# AT91SAM9M10 register map
Vendor: Atmel; File version: 20130207
CPU: 
Registers are 32-bit, read-write, no defined reset value unless marked. A register's access mark holds for its fields unless they carry their own. Offsets are from the block's base; [hi:lo] are bit positions; {n}, {i} and the like mark numbered series.

## ISI — Image Sensor Interface
Base 0xFFFB4000
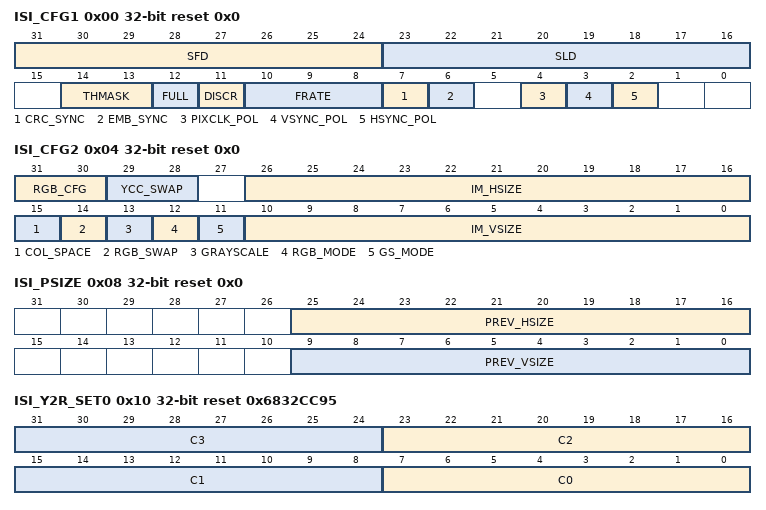
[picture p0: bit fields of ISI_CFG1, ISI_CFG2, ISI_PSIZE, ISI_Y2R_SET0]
0x00 ISI_CFG1 reset 0x0 — ISI Configuration 1 Register
  [31:24] SFD — Start of Frame Delay
  [23:16] SLD — Start of Line Delay
  [14:13] THMASK — Threshold Mask
  [12] FULL — Full Mode is Allowed
  [11] DISCR — Disable Codec Request
  [10:8] FRATE — Frame Rate [0..7]
  [7] CRC_SYNC — Embedded Synchronization Correction
  [6] EMB_SYNC — Embedded Synchronization
  [4] PIXCLK_POL — Pixel Clock Polarity
  [3] VSYNC_POL — Vertical Synchronization Polarity
  [2] HSYNC_POL — Horizontal Synchronization Polarity
0x04 ISI_CFG2 reset 0x0 — ISI Configuration 2 Register
  [31:30] RGB_CFG — Defines RGB Pattern when RGB_MODE is set to 1
  [29:28] YCC_SWAP — Defines the YCC Image Data
  [26:16] IM_HSIZE — Horizontal Size of the Image Sensor [0..2047]
  [15] COL_SPACE — Color Space for the Image Data
  [14] RGB_SWAP
  [13] GRAYSCALE
  [12] RGB_MODE — RGB Input Mode:
  [11] GS_MODE
  [10:0] IM_VSIZE — Vertical Size of the Image Sensor [0..2047]:
0x08 ISI_PSIZE reset 0x0 — ISI Preview Size Register
  [25:16] PREV_HSIZE — Horizontal Size for the Preview Path
  [9:0] PREV_VSIZE — Vertical Size for the Preview Path
0x0C ISI_PDECF reset 0x10 — ISI Preview Decimation Factor Register
  [7:0] DEC_FACTOR — Decimation Factor
0x10 ISI_Y2R_SET0 reset 0x6832CC95 — ISI CSC YCrCb To RGB Set 0 Register
  [8n+7:8n] C{n} (n=0..3) — Color Space Conversion Matrix Coefficient C{n}
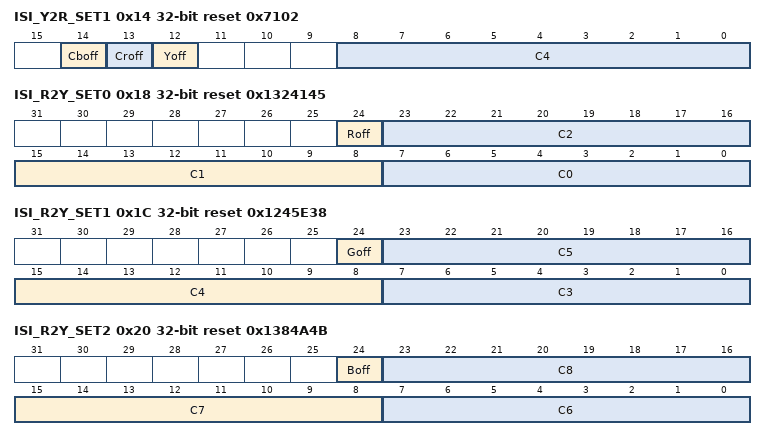
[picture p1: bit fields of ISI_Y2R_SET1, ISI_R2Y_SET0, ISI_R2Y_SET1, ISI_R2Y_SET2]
0x14 ISI_Y2R_SET1 reset 0x7102 — ISI CSC YCrCb To RGB Set 1 Register
  [14] Cboff — Color Space Conversion Blue Chrominance Default Offset
  [13] Croff — Color Space Conversion Red Chrominance Default Offset
  [12] Yoff — Color Space Conversion Luminance Default Offset
  [8:0] C4 — Color Space Conversion Matrix Coefficient C4
0x18 ISI_R2Y_SET0 reset 0x1324145 — ISI CSC RGB To YCrCb Set 0 Register
  [24] Roff — Color Space Conversion Red Component Offset
  [23:16] C2 — Color Space Conversion Matrix Coefficient C2
  [15:8] C1 — Color Space Conversion Matrix Coefficient C1
  [7:0] C0 — Color Space Conversion Matrix Coefficient C0
0x1C ISI_R2Y_SET1 reset 0x1245E38 — ISI CSC RGB To YCrCb Set 1 Register
  [24] Goff — Color Space Conversion Green Component Offset
  [23:16] C5 — Color Space Conversion Matrix Coefficient C5
  [15:8] C4 — Color Space Conversion Matrix Coefficient C4
  [7:0] C3 — Color Space Conversion Matrix Coefficient C3
0x20 ISI_R2Y_SET2 reset 0x1384A4B — ISI CSC RGB To YCrCb Set 2 Register
  [24] Boff — Color Space Conversion Blue Component Offset
  [23:16] C8 — Color Space Conversion Matrix Coefficient C8
  [15:8] C7 — Color Space Conversion Matrix Coefficient C7
  [7:0] C6 — Color Space Conversion Matrix Coefficient C6
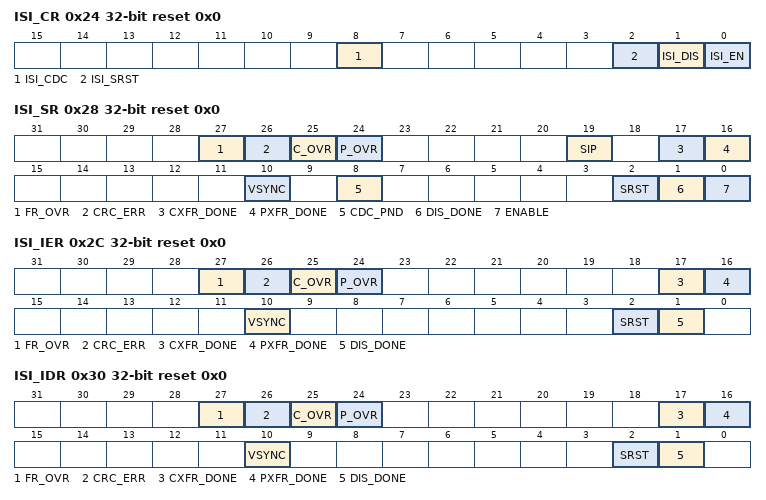
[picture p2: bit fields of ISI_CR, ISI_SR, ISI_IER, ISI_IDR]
0x24 ISI_CR wo reset 0x0 — ISI Control Register
  [8] ISI_CDC — ISI Codec Request
  [2] ISI_SRST — ISI Software Reset Request
  [1] ISI_DIS — ISI Module Disable Request
  [0] ISI_EN — ISI Module Enable Request
0x28 ISI_SR ro reset 0x0 — ISI Status Register
  [27] FR_OVR — Frame Rate Overrun
  [26] CRC_ERR — CRC Synchronization Error
  [25] C_OVR — Codec Datapath Overflow
  [24] P_OVR — Preview Datapath Overflow
  [19] SIP — Synchronization in Progress (this is a status bit)
  [17] CXFR_DONE — Codec DMA Transfer has Terminated.
  [16] PXFR_DONE — Preview DMA Transfer has Terminated.
  [10] VSYNC — Vertical Synchronization
  [8] CDC_PND — Pending Codec Request (this bit is a status bit)
  [2] SRST — Module Software Reset Request has Terminated
  [1] DIS_DONE — Module Disable Request has Terminated
  [0] ENABLE
0x2C ISI_IER wo reset 0x0 — ISI Interrupt Enable Register
  [27] FR_OVR — Frame Rate Overflow Interrupt Enable
  [26] CRC_ERR — Embedded Synchronization CRC Error Interrupt Enable
  [25] C_OVR — Codec Datapath Overflow Interrupt Enable
  [24] P_OVR — Preview Datapath Overflow Interrupt Enable
  [17] CXFR_DONE — Codec DMA Transfer Done Interrupt Enable
  [16] PXFR_DONE — Preview DMA Transfer Done Interrupt Enable
  [10] VSYNC — Vertical Synchronization Interrupt Enable
  [2] SRST — Software Reset Interrupt Enable
  [1] DIS_DONE — Disable Done Interrupt Enable
0x30 ISI_IDR wo reset 0x0 — ISI Interrupt Disable Register
  [27] FR_OVR — Frame Rate Overflow Interrupt Disable
  [26] CRC_ERR — Embedded Synchronization CRC Error Interrupt Disable
  [25] C_OVR — Codec Datapath Overflow Interrupt Disable
  [24] P_OVR — Preview Datapath Overflow Interrupt Disable
  [17] CXFR_DONE — Codec DMA Transfer Done Interrupt Disable
  [16] PXFR_DONE — Preview DMA Transfer Done Interrupt Disable
  [10] VSYNC — Vertical Synchronization Interrupt Disable
  [2] SRST — Software Reset Interrupt Disable
  [1] DIS_DONE — Disable Done Interrupt Disable
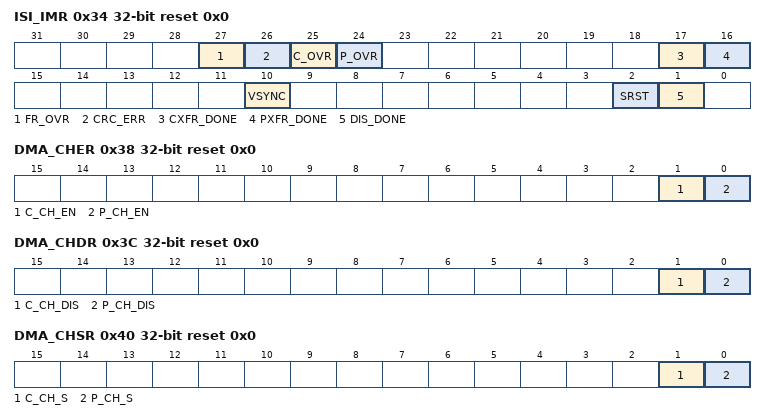
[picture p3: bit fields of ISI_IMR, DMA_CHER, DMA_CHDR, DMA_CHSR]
0x34 ISI_IMR ro reset 0x0 — ISI Interrupt Mask Register
  [27] FR_OVR — Frame Rate Overrun
  [26] CRC_ERR — CRC Synchronization Error
  [25] C_OVR — FIFO Codec Overflow
  [24] P_OVR — FIFO Preview Overflow
  [17] CXFR_DONE — Codec DMA Transfer Interrupt
  [16] PXFR_DONE — Preview DMA Transfer Interrupt
  [10] VSYNC — Vertical Synchronization
  [2] SRST — Software Reset Completed
  [1] DIS_DONE — Module Disable Operation Completed
0x38 DMA_CHER wo reset 0x0 — DMA Channel Enable Register
  [1] C_CH_EN — Codec Channel Enable
  [0] P_CH_EN — Preview Channel Enable
0x3C DMA_CHDR wo reset 0x0 — DMA Channel Disable Register
  [1] C_CH_DIS, [0] P_CH_DIS
0x40 DMA_CHSR ro reset 0x0 — DMA Channel Status Register
  [1] C_CH_S, [0] P_CH_S
0x44 DMA_P_ADDR reset 0x0 — DMA Preview Base Address Register
  [31:2] P_ADDR — Preview Image Base Address. (This address is word aligned.)
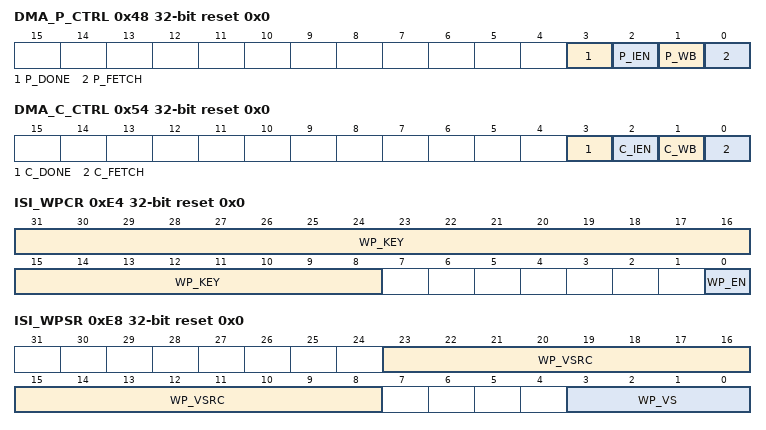
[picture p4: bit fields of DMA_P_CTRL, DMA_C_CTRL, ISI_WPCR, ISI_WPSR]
0x48 DMA_P_CTRL reset 0x0 — DMA Preview Control Register
  [3] P_DONE — (This field is only updated in the memory.)
  [2] P_IEN — Transfer Done Flag Control
  [1] P_WB — Descriptor Writeback Control Field
  [0] P_FETCH — Descriptor Fetch Control Field
0x4C DMA_P_DSCR reset 0x0 — DMA Preview Descriptor Address Register
  [31:2] P_DSCR — Preview Descriptor Base Address (This address is word aligned.)
0x50 DMA_C_ADDR reset 0x0 — DMA Codec Base Address Register
  [31:2] C_ADDR — Codec Image Base Address (This address is word aligned.)
0x54 DMA_C_CTRL reset 0x0 — DMA Codec Control Register
  [3] C_DONE — (This field is only updated in the memory.)
  [2] C_IEN — Transfer Done flag control
  [1] C_WB — Descriptor Writeback Control Field
  [0] C_FETCH — Descriptor Fetch Control Field
0x58 DMA_C_DSCR reset 0x0 — DMA Codec Descriptor Address Register
  [31:2] C_DSCR — Codec Descriptor Base Address (This address is word aligned.)
0xE4 ISI_WPCR reset 0x0 — Write Protection Control Register
  [31:8] WP_KEY — Write Protection KEY Password
  [0] WP_EN — Write Protection Enable
0xE8 ISI_WPSR ro reset 0x0 — Write Protection Status Register
  [23:8] WP_VSRC — Write Protection Violation Source
  [3:0] WP_VS — Write Protection Violation Status
